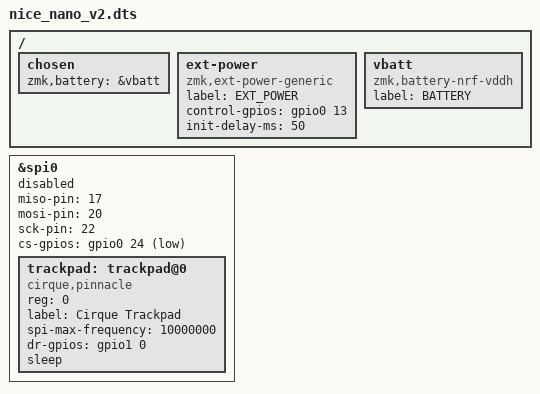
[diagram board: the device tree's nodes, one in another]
/*
 * Copyright (c) 2021 The ZMK Contributors
 *
 * SPDX-License-Identifier: MIT
 */

/dts-v1/;
#include "nice_nano.dtsi"

/ {
	chosen {
		zmk,battery = &vbatt;
	};

	ext-power {
		compatible = "zmk,ext-power-generic";
		label = "EXT_POWER";
		control-gpios = <&gpio0 13 GPIO_ACTIVE_HIGH>;
		init-delay-ms = <50>;
	};

	vbatt: vbatt {
		compatible = "zmk,battery-nrf-vddh";
		label = "BATTERY";
	};
};


&spi0 {
    /*
        1 -> sck -> P0.22 -> left 7
        2 -> miso -> P0.17 -> left 5
        3 -> cs -> P0.24 -> left 8
        4 -> dr -> P1.0 -> left 9
        5 -> mosi -> P0.20 -> left 6
        11 -> gnd -> left 3, left 4, right 2
        12 -> vdd -> right 4
    */
    status = "disabled";
    miso-pin = <17>; // P0.17
    mosi-pin = <20>; // P0.20
    sck-pin = <22>; // P0.22
    cs-gpios = <&gpio0 24 GPIO_ACTIVE_LOW>; // P0.24

    trackpad: trackpad@0 {
        compatible = "cirque,pinnacle";
        // status = "okay";
        reg = <0>;
        label = "Cirque Trackpad";
        spi-max-frequency = <10000000>;
        dr-gpios = <&gpio1 0 GPIO_ACTIVE_HIGH>; // P1.0
        // invert-x;
        sleep;
        /* no-taps; */
    };
};

nice_nano_spi: &spi0 {};
